# cslr_spi_001 register map
Vendor: Texas Instruments
Peripheral module from a debugger description file.
Registers are 32-bit, access not given, reset 0x0 unless marked. A register's access mark holds for its fields unless they carry their own. Offsets are as the file gives them; lines under a group give offsets from that group; [hi:lo] are bit positions; {n}, {i} and the like mark numbered series; 'fields as' and 'values as' point back to an identical list; <NAME> marks a mode.

## SPI — Serial Port Interface
0x00 SPIGCR0 — SPI Global Control Register 0
  [0] RESET rw — Soft Reset
    0=Yes; 1=No
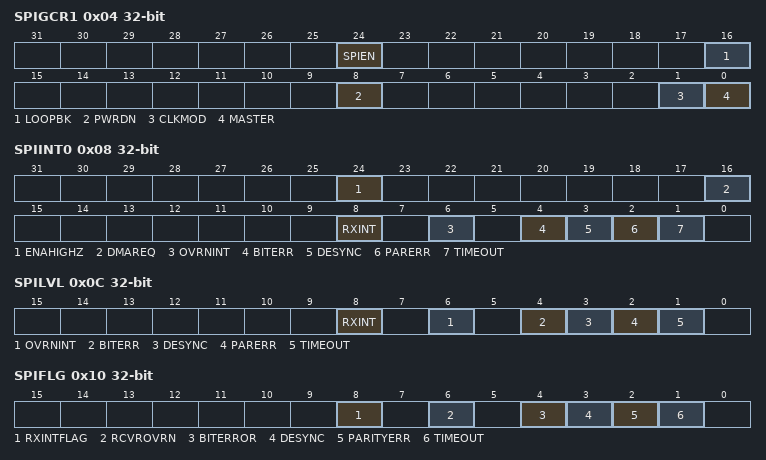
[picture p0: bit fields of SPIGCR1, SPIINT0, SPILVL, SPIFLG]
0x04 SPIGCR1 — SPI Global control regsiter 1
  [24] SPIEN rw — SPI Enable
    0=InReset (Module in reset); 1=Active (Activates SPI)
  [16] LOOPBK rw — Internal loopback test mode
    0=Disable; 1=Enable
  [8] PWRDN rw — SPI Power Down Mode
    0=Active; 1=Pwrdn
  [1] CLKMOD rw — Clock Mode
    0=External; 1=Internal
  [0] MASTER rw — Master: SPISIMO/SPISOMI pin direction determination
    0=No; 1=Yes
0x08 SPIINT0 — Interrupt Register
  [all] fields
    0=Disable; 1=Enable
  [24] ENAHIGHZ rw — SPIENA pin high-z enable
  [16] DMAREQ rw — DMA Request Enable
  [8] RXINT rw — RX interrupt enable
  [6] OVRNINT rw — Overrun interrupt enable
  [4] BITERR rw — Bit error enable
  [3] DESYNC rw — desync interrupt eanble
  [2] PARERR rw — Parity error enable
  [1] TIMEOUT rw — Time out interrupt enable
0x0C SPILVL — Maps the interrupts to different interrupt lines.
  [all] fields
    0=INT0; 1=INT1
  [8] RXINT rw — RX interrupt Level
  [6] OVRNINT rw — RX Overrun Interrupt Level
  [4] BITERR rw — Bit error interrupt Level
  [3] DESYNC — Desync Interrupt Level
  [2] PARERR rw — Parity Interrupt Level
  [1] TIMEOUT rw — Time out Interrupt Level
0x10 SPIFLG — SPI Flag Status register
  [all] fields
    0=No; 1=Yes
  [8] RXINTFLAG rw — RX interrupt flag
  [6] RCVROVRN rw — RX overrun flag
  [4] BITERROR rw — Bit error flag
  [3] DESYNC rw — Desync error flag
  [2] PARITYERR rw — Parity Error Flag
  [1] TIMEOUT rw — Time out error flag
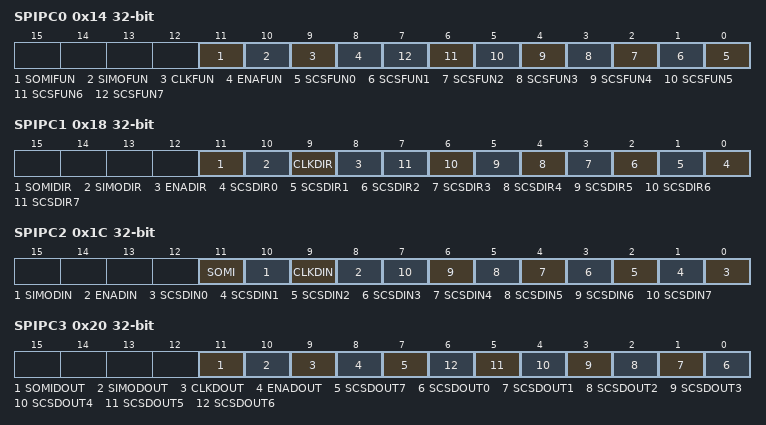
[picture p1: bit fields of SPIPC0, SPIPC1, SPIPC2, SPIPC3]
0x14 SPIPC0 — Pin Control Register
  [all] fields
    0=GPIO; 1=SPI
  [11] SOMIFUN rw — Slave out, master in function
  [10] SIMOFUN rw — Slave in, Master out
  [9] CLKFUN rw — SPI clock function
  [8] ENAFUN rw — SPIENA function
  [n] SCSFUN{n} rw (n=0..7) — SPISCSx function
0x18 SPIPC1 — SPI Pin control register 1
  [all] fields
    0=In; 1=Out
  [11] SOMIDIR rw — Slave out, master direction
  [10] SIMODIR rw — Slave in, Master out direction
  [9] CLKDIR rw — SPI clock direction
  [8] ENADIR rw — SPIENA direction
  [n] SCSDIR{n} rw (n=0..7) — SPISCSx direction
0x1C SPIPC2 — SPI Pin control register 2
  [all] fields
    0=LO; 1=HI
  [11] SOMI ro — Slave out, master data in
  [10] SIMODIN ro — Slave in, Master out data in
  [9] CLKDIN ro — SPI clock data in
  [8] ENADIN ro — SPIENA data in
  [n] SCSDIN{n} ro (n=0..7) — SPISCSx data in
0x20 SPIPC3 — SPI Pin control register 3
  [all] fields
    0=LO; 1=HI
  [11] SOMIDOUT rw — Slave out, master in data out write
  [10] SIMODOUT rw — Slave in, Master out
  [9] CLKDOUT rw — SPI clock data out write
  [8] ENADOUT rw — SPIENA data out write
  [7] SCSDOUT7 rw — SPISCSx data out write
  [n] SCSDOUT{n} rw (n=0..6)
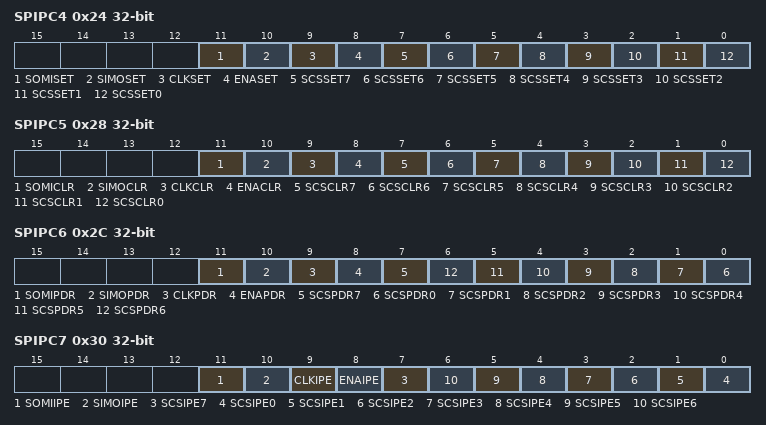
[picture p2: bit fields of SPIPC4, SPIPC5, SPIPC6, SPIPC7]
0x24 SPIPC4 — SPI Pin Control Register 4
  [11] SOMISET rw — Slave out, master in dataout set.
    0=LO (Write: 0: Has no effect 1: Logic 1 placed on SPISOMI pin. Read 0: Current Value on SPISOMI pin is logic 0. 1: Current value on SPISOMI pin is logic 1.); 1=HI
  [10] SIMOSET rw — Slave in, Master out
    0=LO (Write: 0: Has no effect 1: Logic 1 placed on SPISIMO pin. Read 0: Current Value on SPISIMO pin is logic 0. 1: Current value on SPISIMO pin is logic 1.); 1=HI
  [9] CLKSET rw — SPI clock dataout set.
    0=LO (Write: 0: Has no effect 1: Logic 1 placed on SPICLK pin. Read 0: Current Value on SPICLK pin is logic 0. 1: Current value on SPICLK pin is logic 1.); 1=HI
  [8] ENASET rw — SPIENA dataout set.
    0=LO (Write: 0: Has no effect 1: Logic 1 placed on SPIENA pin. Read 0: Current Value on SPIENA pin is logic 0. 1: Current value on SPIENA pin is logic 1.); 1=HI
  [7] SCSSET7 rw — SPISCSx dataout set.
    values as SOMISET
  [6] SCSSET6 rw
    values as SIMOSET
  [5] SCSSET5 rw
    values as CLKSET
  [4] SCSSET4 rw
    values as ENASET
  [3] SCSSET3 rw
    values as SOMISET
  [2] SCSSET2 rw
    values as SIMOSET
  [1] SCSSET1 rw
    values as CLKSET
  [0] SCSSET0 rw
    values as ENASET
0x28 SPIPC5 — SPI Pin Control Register
  [11] SOMICLR rw — Slave out, master in dataout clear.
    0=LO (Write: 0: Has no effect 1: Logic 0 placed on SPISOMI pin. Read 0: Current Value on SPISOMI pin is logic 0. 1: Current value on SPISOMI pin is logic 1.); 1=HI
  [10] SIMOCLR rw — Slave in, Master out
    0=LO (Write: 0: Has no effect 1: Logic 0 placed on SPISIMO pin. Read 0: Current Value on SPISIMO pin is logic 0. 1: Current value on SPISIMO pin is logic 1.); 1=HI
  [9] CLKCLR rw — SPI clock dataout clear.
    0=LO (Write: 0: Has no effect 1: Logic 0 placed on SPICLK pin. Read 0: Current Value on SPICLK pin is logic 0. 1: Current value on SPICLK pin is logic 1.); 1=HI
  [8] ENACLR rw — SPIENA dataout clear.
    0=LO (Write: 0: Has no effect 1: Logic 0 placed on SPIENA pin. Read 0: Current Value on SPIENA pin is logic 0. 1: Current value on SPIENA pin is logic 1.); 1=HI
  [7] SCSCLR7 rw — SPISCSx dataout clear.
    values as SOMICLR
  [6] SCSCLR6 rw — SPISCSx dataout clear.
    values as SIMOCLR
  [5] SCSCLR5 rw — SPISCSx dataout clear.
    values as CLKCLR
  [4] SCSCLR4 rw — SPISCSx dataout clear.
    values as ENACLR
  [3] SCSCLR3 rw — SPISCSx dataout clear.
    values as SOMICLR
  [2] SCSCLR2 rw — SPISCSx dataout clear.
    values as SIMOCLR
  [1] SCSCLR1 rw — SPISCSx dataout clear.
    values as CLKCLR
  [0] SCSCLR0 rw — SPISCSx dataout clear.
    values as ENACLR
0x2C SPIPC6 — SPI Pin Control Register 6
  [11] SOMIPDR rw — Slave out, master in Open Drain Enable
    0=Logic1 (SOMIDIR=1, SOMIDOUT=1 0: Output value on SPISOMI pin is .ogic 1 1: Output value on SPISOMI pin is Tri-stated.); 1=Tristate
  [10] SIMOPDR rw — Slave in, Master out
    0=Logic1 (0: Output value on SPISIMO pin is logic '1'. 1: Output value on SPISIMO pin is Tri-stated.); 1=Tristate
  [9] CLKPDR rw — SPI clock Open Drain Enable
    0=Logic1 (0: Output value on SPICLK is logic '1'. 1: Output value on SPICLK is Tr-stated.); 1=Tristate
  [8] ENAPDR rw — SPIENA Open Drain Enable
    0=Logic1 (0: Output value on SPIENA pin is logic '1'. 1:Output value on SPIENA pin is tri-stated.); 1=Tristate
  [7] SCSPDR7 rw — SPISCSx Open Drain Enable
    0=Logic1 (0: Output value on SPISCSx pinis logic '1'. 1: Output value on SPISCSx is tri-stated.); 1=Tristate
  [n] SCSPDR{n} rw (n=0..6) — SPISCSx Open Drain Enable
    0=Logic1; 1=Tristate
0x30 SPIPC7 — SPI Pin Control Register 7
  [11] SOMIIPE rw — Slave out, master in Pull Control Enable
    0=Enable (SOMIDIR=0 0: Pull Control on SPISOMI pin is enabled. 1: Pull Control on SPISOMI pin is Disabled.); 1=Disable
  [10] SIMOIPE rw — Slave in, Master out Pull Control Enable
    0=Enable (0: Pull Control on SPISIMO pin is enabled. 1: Pull Control on SPISIMO pin is Disabled.); 1=Disable
  [9] CLKIPE rw — SPI clock Pull Control Enable
    0=Enable (0: Pull Control on SPICLK is enabled. 1: Pull Control on SPICLK is Disabled); 1=Disable
  [8] ENAIPE rw — SPIENA Pull Control Enable
    0=Enable (0: Pull Control on SPIENA pin is enabled. 1:Pull Control on SPIENA pin is disabled..); 1=Disable
  [7] SCSIPE7 rw — SPISCSx Pull Control Enable
    0=Enable (0: Pull Control on SPISCSx pin is enabled. 1: Pull Control on SPISCSx is disabled.); 1=Disable
  [n] SCSIPE{n} rw (n=0..6) — SPISCSx Pull Control Enable
    0=Enable; 1=Disable
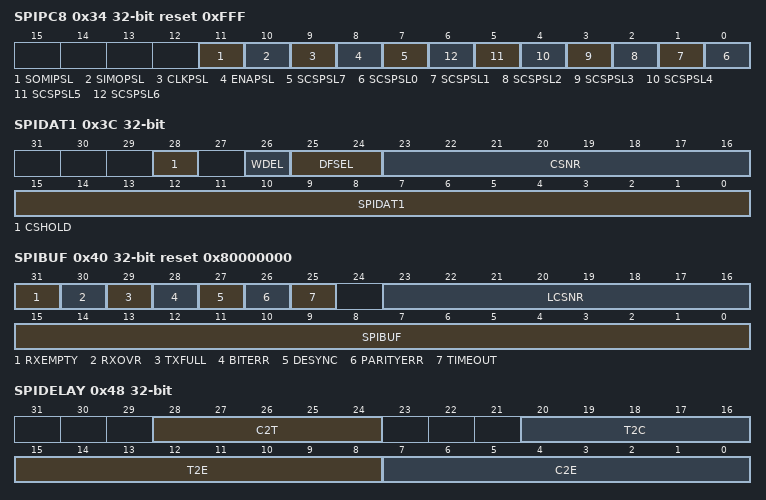
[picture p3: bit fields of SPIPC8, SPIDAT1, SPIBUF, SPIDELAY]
0x34 SPIPC8 reset 0xFFF — SPI Pin Control Register 8
  [11] SOMIPSL rw — Slave out, master in Pull Select
    0=Pulldown (SOMIDIR=0 0: Pull Control on SPISOMI pin is enabled. 1: Pull Control on SPISOMI pin is Disabled.); 1=Pullup
  [10] SIMOPSL rw — Slave in, Master out Pull Select
    0=Pulldown (0: Pull Control on SPISIMO pin is enabled. 1: Pull Control on SPISIMO pin is Disabled.); 1=Pullup
  [9] CLKPSL rw — SPI clock Pull Select
    0=Pulldown (0: Pull Control on SPICLK is enabled. 1: Pull Control on SPICLK is Disabled); 1=Pullup
  [8] ENAPSL rw — SPIENA Pull Select
    0=Pulldown (0: Pull Control on SPIENA pin is enabled. 1:Pull Control on SPIENA pin is disabled..); 1=Pullup
  [7] SCSPSL7 rw — SPISCSx Pull Select
    0=Pulldown (0: Pull Control on SPISCSx pin is enabled. 1: Pull Control on SPISCSx is disabled.); 1=Pullup
  [n] SCSPSL{n} rw (n=0..6) — SPISCSx Pull Select
    0=Pulldown; 1=Pullup
0x38 SPIDAT0 — SPI Shift Register
  [15:0] SPIDAT0 rw — SPIDAT0 Shift Register
0x3C SPIDAT1 — SPI Shift register
  [28] CSHOLD rw — Chip Select Hold Mode.
    0=No (0: Chip Select de-activated. 1: Chip Select active.); 1=Yes
  [26] WDEL rw — Delay Counter Enable.
    0=NoDelay (0: No Delay Inserted. 1: After the transaction WDELAY of the corresponding data format is loaded into the delay counter.); 1=Delay
  [25:24] DFSEL rw — Data Word Format Select.
    0=FMT0 (00: DWF 0 selected. 01; DWF 1 selected. 10: DWF 2 selected. 11: DWF 3 selected.); 1=FMT1; 2=FMT2; 3=FMT3
  [23:16] CSNR rw — Chip Select no.
  [15:0] SPIDAT1 rw — SPI shift data 1.
0x40 SPIBUF reset 0x80000000 — Buffer register
  [31] RXEMPTY ro — Receive Data buffer empty
    0=Yes; 1=No
  [30] RXOVR ro — RX data buffer overrun
    0=No; 1=Yes
  [29] TXFULL ro — TX data buffer full.
    0=No; 1=Yes
  [28] BITERR ro — Bit error: mismatch of the transmitted data and internal transmit data.
    0=No; 1=Yes
  [27] DESYNC ro — Desynchronization of the slave device.
    0=No; 1=Yes
  [26] PARITYERR ro — Parity Error.
    0=No; 1=Yes
  [25] TIMEOUT ro
    0=No; 1=Yes
  [23:16] LCSNR ro — Last Chip Select No.
  [15:0] SPIBUF ro — MibSPI Buffer.
0x44 SPIEMU — SPI Emulation Register
  [15:0] SPIEMU ro — MibSPI Emulation
0x48 SPIDELAY
  [28:24] C2T rw — chip-select-active-to-transmit-start-delay
  [20:16] T2C rw — Transmit-end-to-chip-select-inactive-delay.
  [15:8] T2E rw — Transmit-data-finished-to-ENA-pin-inactive-time-out
  [7:0] C2E rw — Chip-select-active-to-enable-signal-active-time-out.
0x4C SPIDEF reset 0xFF — SPI Default Chip Select Register.
  [7:0] CSDEF rw — Chip select Default Pattern.
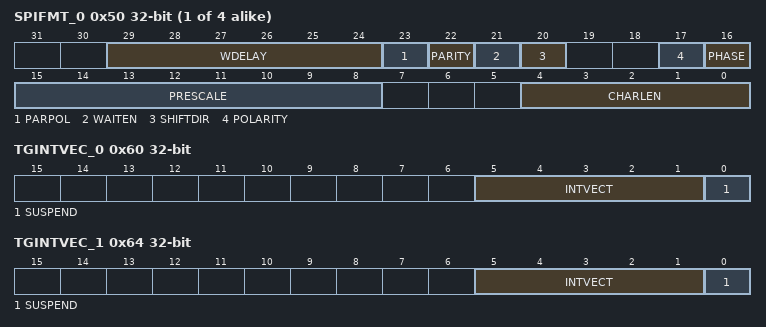
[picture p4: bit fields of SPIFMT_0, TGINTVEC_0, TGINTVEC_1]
{0x50+4i} SPIFMT_{i} (i=0..3) — SPI Data Format Registers
  [29:24] WDELAY rw — Delay in between transmissions for data format x.
  [23] PARPOL rw — Parity Polarity: Even/Odd.
    0=Even; 1=Odd
  [22] PARITY rw — Parity Enable for data format x.
    0=Disable; 1=Enable
  [21] WAITEN rw — Master waits for ENA signal from slave for data format x.
    0=No; 1=Yes
  [20] SHIFTDIR rw — Shift direction for data format x.
    0=MSBFirst; 1=LSBFirst
  [17] POLARITY rw — SPI data format x clock polarity.
    0=InactiveLo; 1=InactiveHi
  [16] PHASE rw — SPI data format x clock delay.
    0=IN; 1=OUT
  [15:8] PRESCALE rw — SPI data format x prescaler.
  [4:0] CHARLEN rw — SPI data format x data word length.
0x60 TGINTVEC_0 — SPI Interrupt Vector Registers
  [5:1] INTVECT ro — Interrupt Vector for interrupt line INT0.
  [0] SUSPEND ro — Transfer suspended/transfer finished interrupt.
    0=FINISH
0x64 TGINTVEC_1 — SPI Interrupt Vector Registers
  fields as TGINTVEC_0
0x70 MIBSPIE — MibSPI Enable Register
  [0] MIBSPIENA rw — MibSPI Enable.
    0=NO; 1=YES
